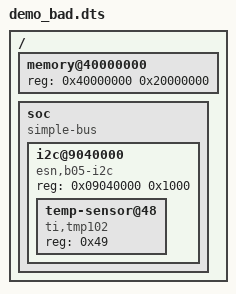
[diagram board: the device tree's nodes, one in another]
// ELX-B05 demo: 흔한 DTS 실수 3개 — dtc -I dts -O dtb -o /dev/null demo_bad.dts
/dts-v1/;

/ {
	#address-cells = <2>;
	#size-cells = <2>;

	memory@40000000 {
		device_type = "memory";
		reg = <0x40000000 0x20000000>;		/* 실수 1: 2+2 셀이어야 하는데 2셀 */
	};

	soc {						/* 실수 2: ranges 가 있는데 unit-address 없음 */
		compatible = "simple-bus";
		#address-cells = <1>;
		#size-cells = <1>;
		ranges = <0x0 0x0 0x0 0x10000000>;

		i2c@9040000 {
			compatible = "esn,b05-i2c";
			reg = <0x09040000 0x1000>;
			#address-cells = <1>;
			#size-cells = <0>;

			temp-sensor@48 {
				compatible = "ti,tmp102";
				reg = <0x49>;			/* 실수 3: 이름은 @48, reg 는 0x49 */
			};
		};
	};
};
